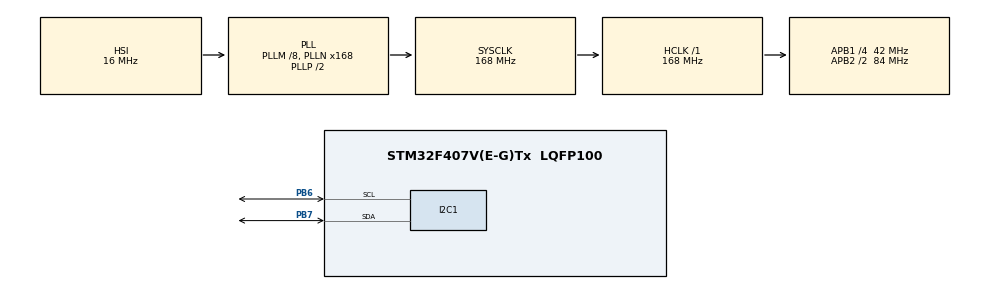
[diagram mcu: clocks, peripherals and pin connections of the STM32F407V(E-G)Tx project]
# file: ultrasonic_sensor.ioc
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Mcu.Family=STM32F4
SH.S_TIM1_CH4.0=TIM1_CH4
RCC.CortexFreq_Value=168000000
NVIC.I2C1_EV_IRQn=true\:0\:0\:false\:false\:true\:true\:true
PE11.GPIO_Label=Echo2
SH.S_TIM5_CH2.0=TIM5_CH2
PC6.GPIO_Label=Echo5
PB0.GPIO_Label=Trig3
RCC.SYSCLKSource=RCC_SYSCLKSOURCE_PLLCLK
ProjectManager.StackSize=0x400
RCC.HCLKFreq_Value=168000000
RCC.APB2TimFreq_Value=168000000
PB6.Signal=I2C1_SCL
SH.S_TIM5_CH3.0=TIM5_CH3
PB6.Mode=I2C
RCC.AHBFreq_Value=168000000
RCC.HSE_VALUE=8000000
PB3.Mode=Trace_Asynchronous_SW
PE13.Signal=S_TIM1_CH3
PE9.Signal=S_TIM1_CH1
PA14.Mode=Trace_Asynchronous_SW
PB1.GPIO_Label=Trig4
PB7.Signal=I2C1_SDA
SH.S_TIM3_CH1.0=TIM3_CH1
NVIC.I2C1_ER_IRQn=true\:0\:0\:false\:false\:true\:true\:true
Mcu.Package=LQFP100
PB1.Signal=S_TIM3_CH4
SH.S_TIM8_CH4.0=TIM8_CH4
PA2.GPIO_Label=Trig7
RCC.APB2CLKDivider=RCC_HCLK_DIV2
PB5.GPIO_Label=Trig2
RCC.APB1TimFreq_Value=84000000
SH.S_TIM5_CH1.0=TIM5_CH1
PB4.Signal=S_TIM3_CH1
SH.S_TIM8_CH3.0=TIM8_CH3
PC9.GPIO_Label=Echo7
PC8.Signal=S_TIM8_CH3
PC6.Signal=S_TIM8_CH1
PE14.GPIO_Label=Echo4
RCC.APB1CLKDivider=RCC_HCLK_DIV4
SH.S_TIM3_CH3.0=TIM3_CH3
PA0-WKUP.GPIO_Label=Trig5
PA0-WKUP.Signal=S_TIM5_CH1
PC8.GPIO_Label=Echo6
PA13.Signal=SYS_JTMS-SWDIO
SH.S_TIM1_CH1.0=TIM1_CH1
ProjectManager.TargetToolchain=STM32CubeIDE
PE11.Signal=S_TIM1_CH2
RCC.LSE_VALUE=32768
PE9.GPIO_Label=Echo1
PA1.Signal=S_TIM5_CH2
SH.S_TIM3_CH2.0=TIM3_CH2
SH.S_TIM8_CH1.0=TIM8_CH1
board=custom
RCC.VCOOutputFreq_Value=336000000
RCC.APB2Freq_Value=84000000
PE14.Signal=S_TIM1_CH4
PB4.GPIO_Label=Trig1
SH.S_TIM1_CH2.0=TIM1_CH2
PA1.GPIO_Label=Trig6
PA13.Mode=Trace_Asynchronous_SW
Mcu.Name=STM32F407V(E-G)Tx
PA2.Signal=S_TIM5_CH3
RCC.48MHZClocksFreq_Value=84000000
PB3.Signal=SYS_JTDO-SWO
RCC.SYSCLKFreq_VALUE=168000000
PB5.Signal=S_TIM3_CH2
PE13.GPIO_Label=Echo3
PB7.Mode=I2C
PA14.Signal=SYS_JTCK-SWCLK
ProjectManager.HeapSize=0x200
SH.S_TIM1_CH3.0=TIM1_CH3
RCC.HSI_VALUE=16000000
NVIC.PriorityGroup=NVIC_PRIORITYGROUP_4
RCC.PLLM=8
RCC.PLLN=168
PC9.Signal=S_TIM8_CH4
RCC.APB1Freq_Value=42000000
PB0.Signal=S_TIM3_CH3
SH.S_TIM3_CH4.0=TIM3_CH4

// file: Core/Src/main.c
/* USER CODE BEGIN Header */
/**
  ******************************************************************************
  * @file           : main.c
  * @brief          : Main program body
  ******************************************************************************
  * @attention
  *
  * <h2><center>&copy; Copyright (c) 2021 STMicroelectronics.
  * All rights reserved.</center></h2>
  *
  * This software component is licensed by ST under BSD 3-Clause license,
  * the "License"; You may not use this file except in compliance with the
  * License. You may obtain a copy of the License at:
  *                        opensource.org/licenses/BSD-3-Clause
  *
  ******************************************************************************
  */
/* USER CODE END Header */
#include "main.h"

/* USER CODE BEGIN Includes */
#include <stdio.h>
#include <stdlib.h>
#include <stdbool.h>
#include <time.h>

#include "ultrasonic_driver.h"
#include "ultrasonic_task.h"
#include "scheduler.h"
#include "util.h"
/* USER CODE END Includes */

I2C_HandleTypeDef hi2c1;
uint8_t cmd;
uint8_t tx_buf[sizeof(int) * ULTRASONIC_NUM_SENSORS];

void SystemClock_Config(void);
static void MX_GPIO_Init(void);
static void MX_I2C1_Init(void);

/* USER CODE BEGIN 0 */
int __io_putchar(int ch) {
	ITM_SendChar(ch);
	return 0;
}

static void ultrasonic_callback(int *pulse_widths) {
	printf("Reached end of schedule.\n");
	for (int i = 0; i < ULTRASONIC_NUM_SENSORS; i++) {
		for (int index = 0; index < sizeof(int); index++) {
			tx_buf[sizeof(int) * i + index] = (pulse_widths[i] >> (24 - 8 * index)) & 0xFF;
		}
		printf("  [%d]: %d\n", i, pulse_widths[i]);
	}

	// Start polling the sensors again.
	app_assert_ok(ultrasonic_task_poll());
}
/* USER CODE END 0 */

int main(void)
{

  /* MCU Configuration--------------------------------------------------------*/

  /* Reset of all peripherals, Initializes the Flash interface and the Systick. */
  HAL_Init();

  /* Configure the system clock */
  SystemClock_Config();

  /* Initialize all configured peripherals */
  MX_GPIO_Init();
  MX_I2C1_Init();

  /* USER CODE BEGIN 2 */
  HAL_I2C_EnableListen_IT(&hi2c1);

    // Configure sensor polling order for ultrasonic task.
  	static const UltrasonicScheduleEntry ultrasonic_schedule[] = {
  		{ 0,  4},
  		{ 1,  5},
  		{ 2,  6},
  		{ 3, -1},
  		{-1, -1} // schedule is terminated by an empty entry
  	};

  	// Initialize the ultrasonic task.
  	ultrasonic_task_init(ultrasonic_schedule, ultrasonic_callback);

  	// Start polling
  	app_assert_ok(ultrasonic_task_poll());
  /* USER CODE END 2 */

  /* Infinite loop */
  while (1) {

    /* USER CODE BEGIN 3 */
	  sched_execute();
	  /* There is nothing useful to do when we're not reacting to interrupts, so sleep until an interrupt occurs.
	   * Note that we don't use HAL_PWR_EnterSLEEPMode here. This is because we want to make sure that if an interrupt occurs
	   * and schedules a task after we determined that there were no more scheduled tasks but before we __WFE(), we want to wake
	   * up immediately to execute the newly scheduled task without ever actually going to sleep. We do this by using the
	   * __SEV() instruction every time we schedule work to be done, so __WFE() will see that the event register is set and
	   * will not sleep. However, HAL_PWR_EnterSLEEPMode uses a special sequence that clears the event register before sleeping,
	   * which, frankly, defeats the purpose of using __WFE() in the first place so I don't know why they do this. */
	  __WFE();
  }
  /* USER CODE END 3 */
}

void SystemClock_Config(void)
{
  RCC_OscInitTypeDef RCC_OscInitStruct = {0};
  RCC_ClkInitTypeDef RCC_ClkInitStruct = {0};

  /** Configure the main internal regulator output voltage
  */
  __HAL_RCC_PWR_CLK_ENABLE();
  __HAL_PWR_VOLTAGESCALING_CONFIG(PWR_REGULATOR_VOLTAGE_SCALE1);
  /** Initializes the RCC Oscillators according to the specified parameters
  * in the RCC_OscInitTypeDef structure.
  */
  RCC_OscInitStruct.OscillatorType = RCC_OSCILLATORTYPE_HSI;
  RCC_OscInitStruct.HSIState = RCC_HSI_ON;
  RCC_OscInitStruct.HSICalibrationValue = RCC_HSICALIBRATION_DEFAULT;
  RCC_OscInitStruct.PLL.PLLState = RCC_PLL_ON;
  RCC_OscInitStruct.PLL.PLLSource = RCC_PLLSOURCE_HSI;
  RCC_OscInitStruct.PLL.PLLM = 8;
  RCC_OscInitStruct.PLL.PLLN = 168;
  RCC_OscInitStruct.PLL.PLLP = RCC_PLLP_DIV2;
  RCC_OscInitStruct.PLL.PLLQ = 4;
  if (HAL_RCC_OscConfig(&RCC_OscInitStruct) != HAL_OK)
  {
    Error_Handler();
  }
  /** Initializes the CPU, AHB and APB buses clocks
  */
  RCC_ClkInitStruct.ClockType = RCC_CLOCKTYPE_HCLK|RCC_CLOCKTYPE_SYSCLK
                              |RCC_CLOCKTYPE_PCLK1|RCC_CLOCKTYPE_PCLK2;
  RCC_ClkInitStruct.SYSCLKSource = RCC_SYSCLKSOURCE_PLLCLK;
  RCC_ClkInitStruct.AHBCLKDivider = RCC_SYSCLK_DIV1;
  RCC_ClkInitStruct.APB1CLKDivider = RCC_HCLK_DIV4;
  RCC_ClkInitStruct.APB2CLKDivider = RCC_HCLK_DIV2;

  if (HAL_RCC_ClockConfig(&RCC_ClkInitStruct, FLASH_LATENCY_5) != HAL_OK)
  {
    Error_Handler();
  }
}

static void MX_I2C1_Init(void)
{

  hi2c1.Instance = I2C1;
  hi2c1.Init.ClockSpeed = 100000;
  hi2c1.Init.DutyCycle = I2C_DUTYCYCLE_2;
  hi2c1.Init.OwnAddress1 = 30;
  hi2c1.Init.AddressingMode = I2C_ADDRESSINGMODE_7BIT;
  hi2c1.Init.DualAddressMode = I2C_DUALADDRESS_DISABLE;
  hi2c1.Init.OwnAddress2 = 0;
  hi2c1.Init.GeneralCallMode = I2C_GENERALCALL_DISABLE;
  hi2c1.Init.NoStretchMode = I2C_NOSTRETCH_DISABLE;
  if (HAL_I2C_Init(&hi2c1) != HAL_OK)
  {
    Error_Handler();
  }

}

static void MX_GPIO_Init(void)
{
  GPIO_InitTypeDef GPIO_InitStruct = {0};

  /* GPIO Ports Clock Enable */
  __HAL_RCC_GPIOA_CLK_ENABLE();
  __HAL_RCC_GPIOB_CLK_ENABLE();
  __HAL_RCC_GPIOE_CLK_ENABLE();
  __HAL_RCC_GPIOC_CLK_ENABLE();

  /*Configure GPIO pins : Trig5_Pin Trig6_Pin Trig7_Pin */
  GPIO_InitStruct.Pin = Trig5_Pin|Trig6_Pin|Trig7_Pin;
  GPIO_InitStruct.Mode = GPIO_MODE_AF_PP;
  GPIO_InitStruct.Pull = GPIO_NOPULL;
  GPIO_InitStruct.Speed = GPIO_SPEED_FREQ_LOW;
  GPIO_InitStruct.Alternate = GPIO_AF2_TIM5;
  HAL_GPIO_Init(GPIOA, &GPIO_InitStruct);

  /*Configure GPIO pins : Trig3_Pin Trig4_Pin Trig1_Pin Trig2_Pin */
  GPIO_InitStruct.Pin = Trig3_Pin|Trig4_Pin|Trig1_Pin|Trig2_Pin;
  GPIO_InitStruct.Mode = GPIO_MODE_AF_PP;
  GPIO_InitStruct.Pull = GPIO_NOPULL;
  GPIO_InitStruct.Speed = GPIO_SPEED_FREQ_LOW;
  GPIO_InitStruct.Alternate = GPIO_AF2_TIM3;
  HAL_GPIO_Init(GPIOB, &GPIO_InitStruct);

  /*Configure GPIO pins : Echo1_Pin Echo2_Pin Echo3_Pin Echo4_Pin */
  GPIO_InitStruct.Pin = Echo1_Pin|Echo2_Pin|Echo3_Pin|Echo4_Pin;
  GPIO_InitStruct.Mode = GPIO_MODE_AF_PP;
  GPIO_InitStruct.Pull = GPIO_NOPULL;
  GPIO_InitStruct.Speed = GPIO_SPEED_FREQ_LOW;
  GPIO_InitStruct.Alternate = GPIO_AF1_TIM1;
  HAL_GPIO_Init(GPIOE, &GPIO_InitStruct);

  /*Configure GPIO pins : Echo5_Pin Echo6_Pin Echo7_Pin */
  GPIO_InitStruct.Pin = Echo5_Pin|Echo6_Pin|Echo7_Pin;
  GPIO_InitStruct.Mode = GPIO_MODE_AF_PP;
  GPIO_InitStruct.Pull = GPIO_NOPULL;
  GPIO_InitStruct.Speed = GPIO_SPEED_FREQ_LOW;
  GPIO_InitStruct.Alternate = GPIO_AF3_TIM8;
  HAL_GPIO_Init(GPIOC, &GPIO_InitStruct);

}

/* USER CODE BEGIN 4 */
void __app_abort(const char *file, int line) {
	printf("Abort: %s:%d\r\n", file, line);
	while (1) {
		// Infinite loop
	}
}

void HAL_I2C_SlaveRxCpltCallback(I2C_HandleTypeDef* hi2c) {
	if (hi2c == &hi2c1) {
		printf("i2c_RxCallback\n");
		printf("cmd = %d\n", cmd);
	}
}

void HAL_I2C_ListenCpltCallback(I2C_HandleTypeDef *hi2c) {
	HAL_I2C_EnableListen_IT(&hi2c1); // Restart
}

void HAL_I2C_AddrCallback(I2C_HandleTypeDef *hi2c, uint8_t TransferDirection, uint16_t AddrMatchCode)
{
	UNUSED(AddrMatchCode);

	if(TransferDirection == I2C_DIRECTION_TRANSMIT)
		HAL_I2C_Slave_Sequential_Receive_IT(&hi2c1, &cmd, 1, I2C_LAST_FRAME);
	else
		HAL_I2C_Slave_Sequential_Transmit_IT(&hi2c1, tx_buf, sizeof(int) * ULTRASONIC_NUM_SENSORS, I2C_LAST_FRAME);

}
/* USER CODE END 4 */

void Error_Handler(void)
{
  __disable_irq();
  while (1)
  {
  }
}

#ifdef  USE_FULL_ASSERT
/**
  * @brief  Reports the name of the source file and the source line number
  *         where the assert_param error has occurred.
  * @param  file: pointer to the source file name
  * @param  line: assert_param error line source number
  * @retval None
  */
void assert_failed(uint8_t *file, uint32_t line)
{
  /* USER CODE BEGIN 6 */
	__app_abort((const char*) file, line);
  /* USER CODE END 6 */
}
#endif /* USE_FULL_ASSERT */

/************************ (C) COPYRIGHT STMicroelectronics *****END OF FILE****/
